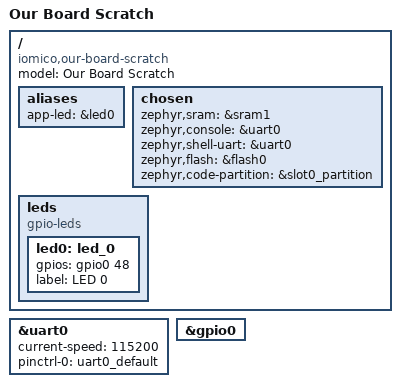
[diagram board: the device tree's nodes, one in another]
/dts-v1/;

#include <espressif/esp32s3/esp32s3_wroom_n8.dtsi>
#include <espressif/partitions_0x0_amp.dtsi>
#include "our_board_scratch-pinctrl.dtsi"

/ {
    model = "Our Board Scratch";
    compatible = "iomico,our-board-scratch";
    aliases {
        app-led = &led0;
    };

    chosen {
        zephyr,sram = &sram1;
        zephyr,console = &uart0;
        zephyr,shell-uart = &uart0;
        zephyr,flash = &flash0;
        zephyr,code-partition = &slot0_partition;
    };

    leds {
        compatible = "gpio-leds";
        led0: led_0 {
            gpios = <&gpio0 48 GPIO_ACTIVE_HIGH>; //GPIO 48
            label = "LED 0";
        };
    };
};

&uart0 {
    status = "okay";
    current-speed = <115200>;
    pinctrl-0 = <&uart0_default>;
    pinctrl-names = "default";
};

&gpio0 {
	status = "okay";
};

